AUTOSAR XML (schema 4-0-3)
package /CalibrationComponents
  parameter sw component type HVSR: data-type-mapping=HVSR_CodeDataTypeMappingsSet
    provide port HVSR_Pport: provided-interface=HVSR_if
      provided-com-specs:
        init-value=1, parameter=KeHVSR_i_statusCurrTR
        init-value=120, parameter=KeHVSR_t_BattPowerOffLossVCU
        init-value=0.5, parameter=KeHVSR_t_CurrTimeOpenNeg
        init-value=0.02500000037252903, parameter=KeHVSR_t_FunctionCallRate
        init-value=10, parameter=KeHVSR_t_RTCTime2Sleep
        init-value=0.07500000298023224, parameter=KeHVSR_t_ShowDownRdyEn
        init-value=CeHVSR_e_BMS_Initialsing, parameter=KeHVSR_e_Ini_State_Val
        init-value=CeHVSR_e_BMS_StayUpReasonReserved, parameter=KeHVSR_e_BMS_StayAwakeReasonOutOvrd
        init-value=CeHVSR_e_BMS_WakeUpReasonDflt, parameter=KeHVSR_e_BMS_Wakeup_reasonOutOvrd
        init-value=CeHVSR_e_Void, parameter=KeHVSR_e_BatteryState_Val
        init-value=CeHVSR_e_StateModeReserved, parameter=KeHVSR_e_StateMode_Val
        init-value=0, parameter=KeHVSR_b_BMSSts_En
        init-value=0, parameter=KeHVSR_b_BatteryState_En
        init-value=0, parameter=KeHVSR_b_BatteryWarm_En
        init-value=0, parameter=KeHVSR_b_BatteryWarm_Val
        init-value=0, parameter=KeHVSR_b_EnableContactors_En
        init-value=0, parameter=KeHVSR_b_EnableHeatCircuitContactors_En
        init-value=0, parameter=KeHVSR_b_FastIsolationActive_En
        init-value=0, parameter=KeHVSR_b_FastIsolationActive_Val
        init-value=0, parameter=KeHVSR_b_Ini_State_En
        init-value=0, parameter=KeHVSR_b_IsolationActive_En
        init-value=0, parameter=KeHVSR_b_IsolationActive_Val
        init-value=0, parameter=KeHVSR_b_NotAllowReqHeat_En
        init-value=0, parameter=KeHVSR_b_NotAllowReqHeat_Val
        init-value=0, parameter=KeHVSR_b_SelfCheckCounter_En
        init-value=0, parameter=KeHVSR_b_ShutdownReady_drv_En
        init-value=0, parameter=KeHVSR_b_ShutdownReady_drv_Val
        init-value=0, parameter=KeHVSR_b_StateMode_En
        init-value=0, parameter=KeHVSR_b_WorkingMode_En
        init-value=0, parameter=KeHVSR_k_BMSSts_Val
        init-value=0, parameter=KeHVSR_k_EnableContactors_Val
        init-value=0, parameter=KeHVSR_k_EnableHeatCircuitContactors_Val
        init-value=0, parameter=KeHVSR_k_SelfCheckCounter_Val
        init-value=0, parameter=KeHVSR_k_WorkingMode_Val
package /HVSR_Code_pkg/HVSR_Code_swc
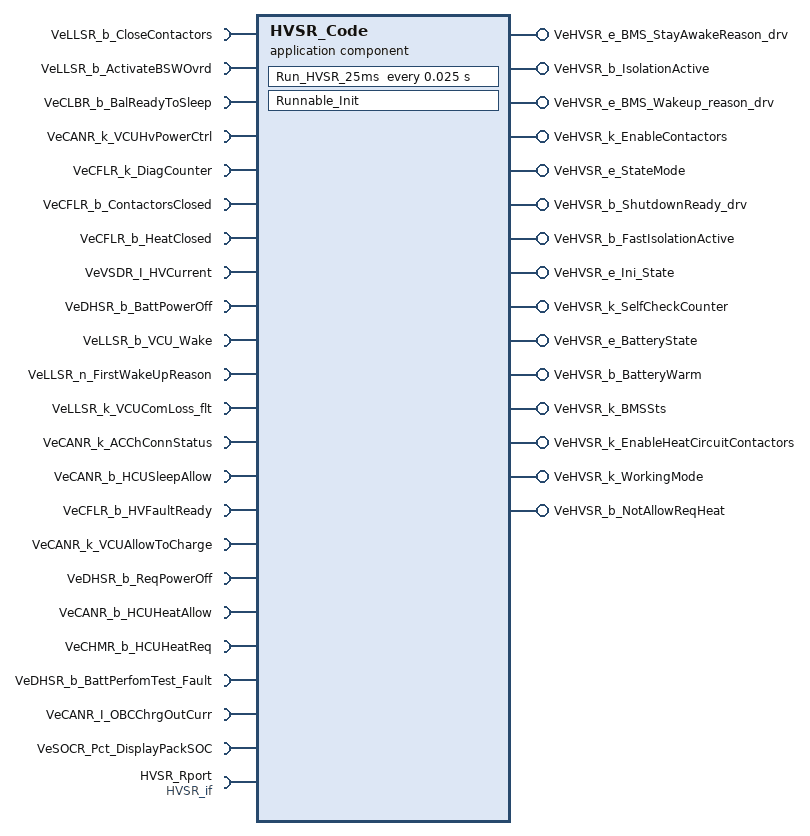
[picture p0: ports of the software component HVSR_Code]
  application sw component type HVSR_Code
    22 x require port:
      VeLLSR_b_CloseContactors: nonqueued-receiver-com-spec{data-element=VeLLSR_b_CloseContactors, init-value=0}, required-interface=VeLLSR_b_CloseContactors
      VeLLSR_b_ActivateBSWOvrd: nonqueued-receiver-com-spec{data-element=VeLLSR_b_ActivateBSWOvrd, init-value=0}, required-interface=VeLLSR_b_ActivateBSWOvrd
      VeCLBR_b_BalReadyToSleep: nonqueued-receiver-com-spec{data-element=VeCLBR_b_BalReadyToSleep, init-value=0}, required-interface=VeCLBR_b_BalReadyToSleep
      VeCANR_k_VCUHvPowerCtrl: nonqueued-receiver-com-spec{data-element=VeCANR_k_VCUHvPowerCtrl, init-value=0}, required-interface=VeCANR_k_VCUHvPowerCtrl
      VeCFLR_k_DiagCounter: nonqueued-receiver-com-spec{data-element=VeCFLR_k_DiagCounter, init-value=0}, required-interface=VeCFLR_k_DiagCounter
      VeCFLR_b_ContactorsClosed: nonqueued-receiver-com-spec{data-element=VeCFLR_b_ContactorsClosed, init-value=0}, required-interface=VeCFLR_b_ContactorsClosed
      VeCFLR_b_HeatClosed: nonqueued-receiver-com-spec{data-element=VeCFLR_b_HeatClosed, init-value=0}, required-interface=VeCFLR_b_HeatClosed
      VeVSDR_I_HVCurrent: nonqueued-receiver-com-spec{data-element=VeVSDR_I_HVCurrent, init-value=0}, required-interface=VeVSDR_I_HVCurrent
      VeDHSR_b_BattPowerOff: nonqueued-receiver-com-spec{data-element=VeDHSR_b_BattPowerOff, init-value=0}, required-interface=VeDHSR_b_BattPowerOff
      VeLLSR_b_VCU_Wake: nonqueued-receiver-com-spec{data-element=VeLLSR_b_VCU_Wake, init-value=0}, required-interface=VeLLSR_b_VCU_Wake
      VeLLSR_n_FirstWakeUpReason: nonqueued-receiver-com-spec{data-element=VeLLSR_n_FirstWakeUpReason, init-value=0}, required-interface=VeLLSR_n_FirstWakeUpReason
      VeLLSR_k_VCUComLoss_flt: nonqueued-receiver-com-spec{data-element=VeLLSR_k_VCUComLoss_flt, init-value=0}, required-interface=VeLLSR_k_VCUComLoss_flt
      VeCANR_k_ACChConnStatus: nonqueued-receiver-com-spec{data-element=VeCANR_k_ACChConnStatus, init-value=0}, required-interface=VeCANR_k_ACChConnStatus
      VeCANR_b_HCUSleepAllow: nonqueued-receiver-com-spec{data-element=VeCANR_b_HCUSleepAllow, init-value=0}, required-interface=VeCANR_b_HCUSleepAllow
      VeCFLR_b_HVFaultReady: nonqueued-receiver-com-spec{data-element=VeCFLR_b_HVFaultReady, init-value=0}, required-interface=VeCFLR_b_HVFaultReady
      VeCANR_k_VCUAllowToCharge: nonqueued-receiver-com-spec{data-element=VeCANR_k_VCUAllowToCharge, init-value=0}, required-interface=VeCANR_k_VCUAllowToCharge
      VeDHSR_b_ReqPowerOff: nonqueued-receiver-com-spec{data-element=VeDHSR_b_ReqPowerOff, init-value=0}, required-interface=VeDHSR_b_ReqPowerOff
      VeCANR_b_HCUHeatAllow: nonqueued-receiver-com-spec{data-element=VeCANR_b_HCUHeatAllow, init-value=0}, required-interface=VeCANR_b_HCUHeatAllow
      VeCHMR_b_HCUHeatReq: nonqueued-receiver-com-spec{data-element=VeCHMR_b_HCUHeatReq, init-value=0}, required-interface=VeCHMR_b_HCUHeatReq
      VeDHSR_b_BattPerfomTest_Fault: nonqueued-receiver-com-spec{data-element=VeDHSR_b_BattPerfomTest_Fault, init-value=0}, required-interface=VeDHSR_b_BattPerfomTest_Fault
      VeCANR_I_OBCChrgOutCurr: nonqueued-receiver-com-spec{data-element=VeCANR_I_OBCChrgOutCurr, init-value=0}, required-interface=VeCANR_I_OBCChrgOutCurr
      VeSOCR_Pct_DisplayPackSOC: nonqueued-receiver-com-spec{data-element=VeSOCR_Pct_DisplayPackSOC, init-value=0}, required-interface=VeSOCR_Pct_DisplayPackSOC
    15 x provide port:
      VeHVSR_e_BMS_StayAwakeReason_drv: nonqueued-sender-com-spec{data-element=VeHVSR_e_BMS_StayAwakeReason_drv, init-value=CeHVSR_e_BMS_StayUpReasonReserved}, provided-interface=VeHVSR_e_BMS_StayAwakeReason_drv
      VeHVSR_b_IsolationActive: nonqueued-sender-com-spec{data-element=VeHVSR_b_IsolationActive, init-value=0}, provided-interface=VeHVSR_b_IsolationActive
      VeHVSR_e_BMS_Wakeup_reason_drv: nonqueued-sender-com-spec{data-element=VeHVSR_e_BMS_Wakeup_reason_drv, init-value=CeHVSR_e_BMS_WakeUpReasonDflt}, provided-interface=VeHVSR_e_BMS_Wakeup_reason_drv
      VeHVSR_k_EnableContactors: nonqueued-sender-com-spec{data-element=VeHVSR_k_EnableContactors, init-value=0}, provided-interface=VeHVSR_k_EnableContactors
      VeHVSR_e_StateMode: nonqueued-sender-com-spec{data-element=VeHVSR_e_StateMode, init-value=CeHVSR_e_StateModeReserved}, provided-interface=VeHVSR_e_StateMode
      VeHVSR_b_ShutdownReady_drv: nonqueued-sender-com-spec{data-element=VeHVSR_b_ShutdownReady_drv, init-value=0}, provided-interface=VeHVSR_b_ShutdownReady_drv
      VeHVSR_b_FastIsolationActive: nonqueued-sender-com-spec{data-element=VeHVSR_b_FastIsolationActive, init-value=0}, provided-interface=VeHVSR_b_FastIsolationActive
      VeHVSR_e_Ini_State: nonqueued-sender-com-spec{data-element=VeHVSR_e_Ini_State, init-value=CeHVSR_e_BMS_Initialsing}, provided-interface=VeHVSR_e_Ini_State
      VeHVSR_k_SelfCheckCounter: nonqueued-sender-com-spec{data-element=VeHVSR_k_SelfCheckCounter, init-value=0}, provided-interface=VeHVSR_k_SelfCheckCounter
      VeHVSR_e_BatteryState: nonqueued-sender-com-spec{data-element=VeHVSR_e_BatteryState, init-value=CeHVSR_e_Void}, provided-interface=VeHVSR_e_BatteryState
      VeHVSR_b_BatteryWarm: nonqueued-sender-com-spec{data-element=VeHVSR_b_BatteryWarm, init-value=0}, provided-interface=VeHVSR_b_BatteryWarm
      VeHVSR_k_BMSSts: nonqueued-sender-com-spec{data-element=VeHVSR_k_BMSSts, init-value=0}, provided-interface=VeHVSR_k_BMSSts
      VeHVSR_k_EnableHeatCircuitContactors: nonqueued-sender-com-spec{data-element=VeHVSR_k_EnableHeatCircuitContactors, init-value=0}, provided-interface=VeHVSR_k_EnableHeatCircuitContactors
      VeHVSR_k_WorkingMode: nonqueued-sender-com-spec{data-element=VeHVSR_k_WorkingMode, init-value=0}, provided-interface=VeHVSR_k_WorkingMode
      VeHVSR_b_NotAllowReqHeat: nonqueued-sender-com-spec{data-element=VeHVSR_b_NotAllowReqHeat, init-value=0}, provided-interface=VeHVSR_b_NotAllowReqHeat
    require port HVSR_Rport: required-interface=HVSR_if
    behavior HVSR_Code: data-type-mapping=HVSR_CodeDataTypeMappingsSet, handle-termination-and-restart=NO-SUPPORT
      static-memorys:
        data VeHVSR_e_ChargeControl: category=VALUE, sw-calibration-access=READ-ONLY, type=TeHVSR_e_VCU_ChargeRequest
        data VeHVSR_e_DischargeControl: category=VALUE, sw-calibration-access=READ-ONLY, type=TeHVSR_e_DischargeControl
      timing event Event_Run_HVSR_25ms: start-on-event=Run_HVSR_25ms, period=0.025
      runnable Runnable_Init: symbol=HVSR_Code_Init
        data-send-points:
          access OUT_VeHVSR_e_BMS_StayAwakeReason_drv_VeHVSR_e_c05067fb4fe2126c: accessed-variable=VeHVSR_e_BMS_StayAwakeReason_drv.VeHVSR_e_BMS_StayAwakeReason_drv
          access OUT_VeHVSR_e_BMS_Wakeup_reason_drv_VeHVSR_e_B_8b60c44b4a0f445a: accessed-variable=VeHVSR_e_BMS_Wakeup_reason_drv.VeHVSR_e_BMS_Wakeup_reason_drv
        parameter access CALPRM_HVSR_Rport_KeHVSR_e_BMS_StayAwakeReasonOutOvrd: accessed-parameter=HVSR_Rport.KeHVSR_e_BMS_StayAwakeReasonOutOvrd
        parameter access CALPRM_HVSR_Rport_KeHVSR_e_BMS_Wakeup_reasonOutOvrd: accessed-parameter=HVSR_Rport.KeHVSR_e_BMS_Wakeup_reasonOutOvrd
      runnable Run_HVSR_25ms
        data-read-access:
          22 x access:
            IN_VeCANR_I_OBCChrgOutCurr_VeCANR_I_OBCChrgOutCurr: accessed-variable=VeCANR_I_OBCChrgOutCurr.VeCANR_I_OBCChrgOutCurr
            IN_VeCANR_b_HCUHeatAllow_VeCANR_b_HCUHeatAllow: accessed-variable=VeCANR_b_HCUHeatAllow.VeCANR_b_HCUHeatAllow
            IN_VeCANR_b_HCUSleepAllow_VeCANR_b_HCUSleepAllow: accessed-variable=VeCANR_b_HCUSleepAllow.VeCANR_b_HCUSleepAllow
            IN_VeCANR_k_ACChConnStatus_VeCANR_k_ACChConnStatus: accessed-variable=VeCANR_k_ACChConnStatus.VeCANR_k_ACChConnStatus
            IN_VeCANR_k_VCUAllowToCharge_VeCANR_k_VCUAllowToCharge: accessed-variable=VeCANR_k_VCUAllowToCharge.VeCANR_k_VCUAllowToCharge
            IN_VeCANR_k_VCUHvPowerCtrl_VeCANR_k_VCUHvPowerCtrl: accessed-variable=VeCANR_k_VCUHvPowerCtrl.VeCANR_k_VCUHvPowerCtrl
            IN_VeCFLR_b_ContactorsClosed_VeCFLR_b_ContactorsClosed: accessed-variable=VeCFLR_b_ContactorsClosed.VeCFLR_b_ContactorsClosed
            IN_VeCFLR_b_HVFaultReady_VeCFLR_b_HVFaultReady: accessed-variable=VeCFLR_b_HVFaultReady.VeCFLR_b_HVFaultReady
            IN_VeCFLR_b_HeatClosed_VeCFLR_b_HeatClosed: accessed-variable=VeCFLR_b_HeatClosed.VeCFLR_b_HeatClosed
            IN_VeCFLR_k_DiagCounter_VeCFLR_k_DiagCounter: accessed-variable=VeCFLR_k_DiagCounter.VeCFLR_k_DiagCounter
            IN_VeCHMR_b_HCUHeatReq_VeCHMR_b_HCUHeatReq: accessed-variable=VeCHMR_b_HCUHeatReq.VeCHMR_b_HCUHeatReq
            IN_VeCLBR_b_BalReadyToSleep_VeCLBR_b_BalReadyToSleep: accessed-variable=VeCLBR_b_BalReadyToSleep.VeCLBR_b_BalReadyToSleep
            IN_VeDHSR_b_BattPerfomTest_Fault_VeDHSR_b_BattPerfomTest_Fault: accessed-variable=VeDHSR_b_BattPerfomTest_Fault.VeDHSR_b_BattPerfomTest_Fault
            IN_VeDHSR_b_BattPowerOff_VeDHSR_b_BattPowerOff: accessed-variable=VeDHSR_b_BattPowerOff.VeDHSR_b_BattPowerOff
            IN_VeDHSR_b_ReqPowerOff_VeDHSR_b_ReqPowerOff: accessed-variable=VeDHSR_b_ReqPowerOff.VeDHSR_b_ReqPowerOff
            IN_VeLLSR_b_ActivateBSWOvrd_VeLLSR_b_ActivateBSWOvrd: accessed-variable=VeLLSR_b_ActivateBSWOvrd.VeLLSR_b_ActivateBSWOvrd
            IN_VeLLSR_b_CloseContactors_VeLLSR_b_CloseContactors: accessed-variable=VeLLSR_b_CloseContactors.VeLLSR_b_CloseContactors
            IN_VeLLSR_b_VCU_Wake_VeLLSR_b_VCU_Wake: accessed-variable=VeLLSR_b_VCU_Wake.VeLLSR_b_VCU_Wake
            IN_VeLLSR_k_VCUComLoss_flt_VeLLSR_k_VCUComLoss_flt: accessed-variable=VeLLSR_k_VCUComLoss_flt.VeLLSR_k_VCUComLoss_flt
            IN_VeLLSR_n_FirstWakeUpReason_VeLLSR_n_FirstWakeUpReason: accessed-variable=VeLLSR_n_FirstWakeUpReason.VeLLSR_n_FirstWakeUpReason
            IN_VeSOCR_Pct_DisplayPackSOC_VeSOCR_Pct_DisplayPackSOC: accessed-variable=VeSOCR_Pct_DisplayPackSOC.VeSOCR_Pct_DisplayPackSOC
            IN_VeVSDR_I_HVCurrent_VeVSDR_I_HVCurrent: accessed-variable=VeVSDR_I_HVCurrent.VeVSDR_I_HVCurrent
        data-send-points:
          15 x access:
            OUT_VeHVSR_e_BMS_StayAwakeReason_drv_VeHVSR_e_c05067fb4fe2126c: accessed-variable=VeHVSR_e_BMS_StayAwakeReason_drv.VeHVSR_e_BMS_StayAwakeReason_drv
            OUT_VeHVSR_b_IsolationActive_VeHVSR_b_IsolationActive: accessed-variable=VeHVSR_b_IsolationActive.VeHVSR_b_IsolationActive
            OUT_VeHVSR_e_BMS_Wakeup_reason_drv_VeHVSR_e_B_8b60c44b4a0f445a: accessed-variable=VeHVSR_e_BMS_Wakeup_reason_drv.VeHVSR_e_BMS_Wakeup_reason_drv
            OUT_VeHVSR_k_EnableContactors_VeHVSR_k_EnableContactors: accessed-variable=VeHVSR_k_EnableContactors.VeHVSR_k_EnableContactors
            OUT_VeHVSR_e_StateMode_VeHVSR_e_StateMode: accessed-variable=VeHVSR_e_StateMode.VeHVSR_e_StateMode
            OUT_VeHVSR_b_ShutdownReady_drv_VeHVSR_b_ShutdownReady_drv: accessed-variable=VeHVSR_b_ShutdownReady_drv.VeHVSR_b_ShutdownReady_drv
            OUT_VeHVSR_b_FastIsolationActive_VeHVSR_b_FastIsolationActive: accessed-variable=VeHVSR_b_FastIsolationActive.VeHVSR_b_FastIsolationActive
            OUT_VeHVSR_e_Ini_State_VeHVSR_e_Ini_State: accessed-variable=VeHVSR_e_Ini_State.VeHVSR_e_Ini_State
            OUT_VeHVSR_k_SelfCheckCounter_VeHVSR_k_SelfCheckCounter: accessed-variable=VeHVSR_k_SelfCheckCounter.VeHVSR_k_SelfCheckCounter
            OUT_VeHVSR_e_BatteryState_VeHVSR_e_BatteryState: accessed-variable=VeHVSR_e_BatteryState.VeHVSR_e_BatteryState
            OUT_VeHVSR_b_BatteryWarm_VeHVSR_b_BatteryWarm: accessed-variable=VeHVSR_b_BatteryWarm.VeHVSR_b_BatteryWarm
            OUT_VeHVSR_k_BMSSts_VeHVSR_k_BMSSts: accessed-variable=VeHVSR_k_BMSSts.VeHVSR_k_BMSSts
            OUT_VeHVSR_k_EnableHeatCircuitContactors_VeHV_8cf5633abaa3a37d: accessed-variable=VeHVSR_k_EnableHeatCircuitContactors.VeHVSR_k_EnableHeatCircuitContactors
            OUT_VeHVSR_k_WorkingMode_VeHVSR_k_WorkingMode: accessed-variable=VeHVSR_k_WorkingMode.VeHVSR_k_WorkingMode
            OUT_VeHVSR_b_NotAllowReqHeat_VeHVSR_b_NotAllowReqHeat: accessed-variable=VeHVSR_b_NotAllowReqHeat.VeHVSR_b_NotAllowReqHeat
        33 x parameter access:
          CALPRM_HVSR_Rport_KeHVSR_b_BMSSts_En: accessed-parameter=HVSR_Rport.KeHVSR_b_BMSSts_En
          CALPRM_HVSR_Rport_KeHVSR_b_BatteryState_En: accessed-parameter=HVSR_Rport.KeHVSR_b_BatteryState_En
          CALPRM_HVSR_Rport_KeHVSR_b_BatteryWarm_En: accessed-parameter=HVSR_Rport.KeHVSR_b_BatteryWarm_En
          CALPRM_HVSR_Rport_KeHVSR_b_BatteryWarm_Val: accessed-parameter=HVSR_Rport.KeHVSR_b_BatteryWarm_Val
          CALPRM_HVSR_Rport_KeHVSR_b_EnableContactors_En: accessed-parameter=HVSR_Rport.KeHVSR_b_EnableContactors_En
          CALPRM_HVSR_Rport_KeHVSR_b_EnableHeatCircuitContactors_En: accessed-parameter=HVSR_Rport.KeHVSR_b_EnableHeatCircuitContactors_En
          CALPRM_HVSR_Rport_KeHVSR_b_FastIsolationActive_En: accessed-parameter=HVSR_Rport.KeHVSR_b_FastIsolationActive_En
          CALPRM_HVSR_Rport_KeHVSR_b_FastIsolationActive_Val: accessed-parameter=HVSR_Rport.KeHVSR_b_FastIsolationActive_Val
          CALPRM_HVSR_Rport_KeHVSR_b_Ini_State_En: accessed-parameter=HVSR_Rport.KeHVSR_b_Ini_State_En
          CALPRM_HVSR_Rport_KeHVSR_b_IsolationActive_En: accessed-parameter=HVSR_Rport.KeHVSR_b_IsolationActive_En
          CALPRM_HVSR_Rport_KeHVSR_b_IsolationActive_Val: accessed-parameter=HVSR_Rport.KeHVSR_b_IsolationActive_Val
          CALPRM_HVSR_Rport_KeHVSR_b_NotAllowReqHeat_En: accessed-parameter=HVSR_Rport.KeHVSR_b_NotAllowReqHeat_En
          CALPRM_HVSR_Rport_KeHVSR_b_NotAllowReqHeat_Val: accessed-parameter=HVSR_Rport.KeHVSR_b_NotAllowReqHeat_Val
          CALPRM_HVSR_Rport_KeHVSR_b_SelfCheckCounter_En: accessed-parameter=HVSR_Rport.KeHVSR_b_SelfCheckCounter_En
          CALPRM_HVSR_Rport_KeHVSR_b_ShutdownReady_drv_En: accessed-parameter=HVSR_Rport.KeHVSR_b_ShutdownReady_drv_En
          CALPRM_HVSR_Rport_KeHVSR_b_ShutdownReady_drv_Val: accessed-parameter=HVSR_Rport.KeHVSR_b_ShutdownReady_drv_Val
          CALPRM_HVSR_Rport_KeHVSR_b_StateMode_En: accessed-parameter=HVSR_Rport.KeHVSR_b_StateMode_En
          CALPRM_HVSR_Rport_KeHVSR_b_WorkingMode_En: accessed-parameter=HVSR_Rport.KeHVSR_b_WorkingMode_En
          CALPRM_HVSR_Rport_KeHVSR_e_BMS_StayAwakeReasonOutOvrd: accessed-parameter=HVSR_Rport.KeHVSR_e_BMS_StayAwakeReasonOutOvrd
          CALPRM_HVSR_Rport_KeHVSR_e_BMS_Wakeup_reasonOutOvrd: accessed-parameter=HVSR_Rport.KeHVSR_e_BMS_Wakeup_reasonOutOvrd
          CALPRM_HVSR_Rport_KeHVSR_e_BatteryState_Val: accessed-parameter=HVSR_Rport.KeHVSR_e_BatteryState_Val
          CALPRM_HVSR_Rport_KeHVSR_e_Ini_State_Val: accessed-parameter=HVSR_Rport.KeHVSR_e_Ini_State_Val
          CALPRM_HVSR_Rport_KeHVSR_e_StateMode_Val: accessed-parameter=HVSR_Rport.KeHVSR_e_StateMode_Val
          CALPRM_HVSR_Rport_KeHVSR_i_statusCurrTR: accessed-parameter=HVSR_Rport.KeHVSR_i_statusCurrTR
          CALPRM_HVSR_Rport_KeHVSR_k_BMSSts_Val: accessed-parameter=HVSR_Rport.KeHVSR_k_BMSSts_Val
          CALPRM_HVSR_Rport_KeHVSR_k_EnableContactors_Val: accessed-parameter=HVSR_Rport.KeHVSR_k_EnableContactors_Val
          CALPRM_HVSR_Rport_KeHVSR_k_EnableHeatCircuitContactors_Val: accessed-parameter=HVSR_Rport.KeHVSR_k_EnableHeatCircuitContactors_Val
          CALPRM_HVSR_Rport_KeHVSR_k_SelfCheckCounter_Val: accessed-parameter=HVSR_Rport.KeHVSR_k_SelfCheckCounter_Val
          CALPRM_HVSR_Rport_KeHVSR_k_WorkingMode_Val: accessed-parameter=HVSR_Rport.KeHVSR_k_WorkingMode_Val
          CALPRM_HVSR_Rport_KeHVSR_t_BattPowerOffLossVCU: accessed-parameter=HVSR_Rport.KeHVSR_t_BattPowerOffLossVCU
          CALPRM_HVSR_Rport_KeHVSR_t_FunctionCallRate: accessed-parameter=HVSR_Rport.KeHVSR_t_FunctionCallRate
          CALPRM_HVSR_Rport_KeHVSR_t_RTCTime2Sleep: accessed-parameter=HVSR_Rport.KeHVSR_t_RTCTime2Sleep
          CALPRM_HVSR_Rport_KeHVSR_t_ShowDownRdyEn: accessed-parameter=HVSR_Rport.KeHVSR_t_ShowDownRdyEn
